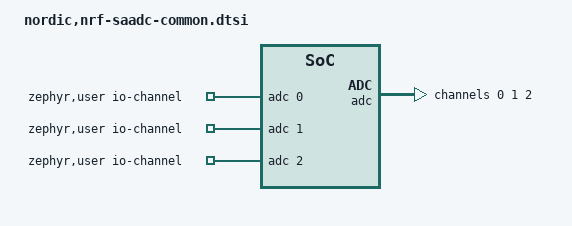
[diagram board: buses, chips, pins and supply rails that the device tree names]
/*
 * SPDX-License-Identifier: Apache-2.0
 *
 * Copyright (c) 2023 Benjamin Björnsson <benjamin.bjornsson@gmail.com>
 */

/ {
	zephyr,user {
		io-channels = <&adc 0>, <&adc 1>, <&adc 2>;
	};
};

&adc {
	#address-cells = <1>;
	#size-cells = <0>;

	channel@0 {
		reg = <0>;
		zephyr,gain = "ADC_GAIN_1_6";
		zephyr,reference = "ADC_REF_INTERNAL";
		zephyr,acquisition-time = <ADC_ACQ_TIME(ADC_ACQ_TIME_MICROSECONDS, 10)>;
		zephyr,input-positive = <NRF_SAADC_AIN2>;
		zephyr,resolution = <10>;
	};

	channel@1 {
		reg = <1>;
		zephyr,gain = "ADC_GAIN_1_6";
		zephyr,reference = "ADC_REF_INTERNAL";
		zephyr,acquisition-time = <ADC_ACQ_TIME(ADC_ACQ_TIME_MICROSECONDS, 10)>;
		zephyr,input-positive = <NRF_SAADC_AIN4>;
		zephyr,resolution = <10>;
	};

	channel@2 {
		reg = <2>;
		zephyr,gain = "ADC_GAIN_1_6";
		zephyr,reference = "ADC_REF_INTERNAL";
		zephyr,acquisition-time = <ADC_ACQ_TIME(ADC_ACQ_TIME_MICROSECONDS, 10)>;
		zephyr,input-positive = <NRF_SAADC_AIN0>;
		zephyr,resolution = <10>;
	};
};
